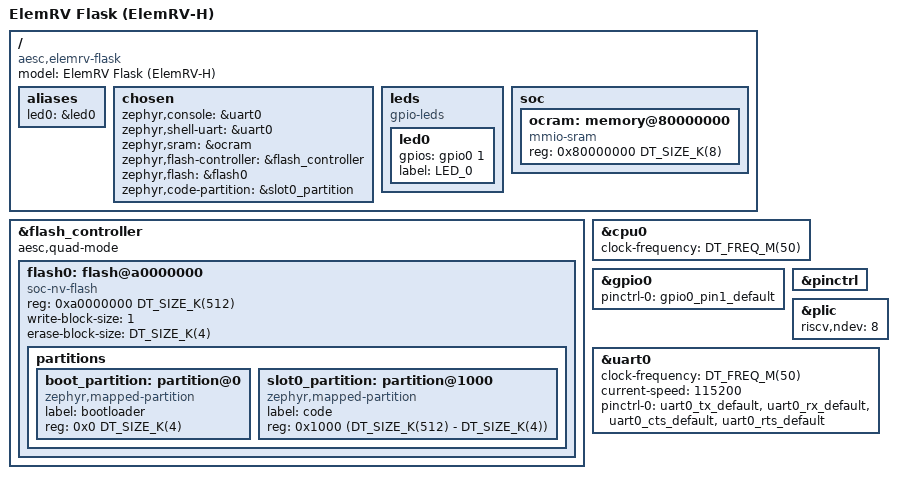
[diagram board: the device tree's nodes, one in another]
/*
 * SPDX-FileCopyrightText: 2026 Aesc Silicon
 *
 * SPDX-License-Identifier: Apache-2.0
 */

/dts-v1/;

#include <aesc/elemrv-h.dtsi>
#include <zephyr/dt-bindings/pwm/pwm.h>
#include "elemrv_flask_elemrv_h-pinctrl.dtsi"

/ {
	model = "ElemRV Flask (ElemRV-H)";
	compatible = "aesc,elemrv-flask";

	aliases {
		led0 = &led0;
	};

	chosen {
		zephyr,console = &uart0;
		zephyr,shell-uart = &uart0;
		zephyr,sram = &ocram;
		zephyr,flash-controller = &flash_controller;
		zephyr,flash = &flash0;
		zephyr,code-partition = &slot0_partition;
	};

	leds: leds {
		compatible = "gpio-leds";

		led0: led0 {
			gpios = <&gpio0 1 GPIO_ACTIVE_HIGH>;
			label = "LED_0";
		};
	};

	soc {
		ocram: memory@80000000 {
			device_type = "memory";
			compatible = "mmio-sram";
			reg = <0x80000000 DT_SIZE_K(8)>;
		};
	};
};

&flash_controller {
	aesc,quad-mode;

	flash0: flash@a0000000 {
		compatible = "soc-nv-flash";
		reg = <0xa0000000 DT_SIZE_K(512)>;
		write-block-size = <1>;
		erase-block-size = <DT_SIZE_K(4)>;
		/* Map the partition offset space onto the XIP window. */
		ranges = <0x0 0xa0000000 DT_SIZE_K(512)>;
		#address-cells = <1>;
		#size-cells = <1>;

		partitions {
			ranges;
			#address-cells = <1>;
			#size-cells = <1>;

			boot_partition: partition@0 {
				compatible = "zephyr,mapped-partition";
				label = "bootloader";
				reg = <0x0 DT_SIZE_K(4)>;
			};

			slot0_partition: partition@1000 {
				compatible = "zephyr,mapped-partition";
				label = "code";
				reg = <0x1000 (DT_SIZE_K(512) - DT_SIZE_K(4))>;
			};
		};
	};
};

&cpu0 {
	clock-frequency = <DT_FREQ_M(50)>;
};

&gpio0 {
	pinctrl-0 = <&gpio0_pin1_default>;
	pinctrl-names = "default";
	status = "okay";
};

&pinctrl {
	status = "okay";
};

&plic {
	riscv,ndev = <8>;
};

&uart0 {
	clock-frequency = <DT_FREQ_M(50)>;
	current-speed = <115200>;
	pinctrl-0 = <&uart0_tx_default
		     &uart0_rx_default
		     &uart0_cts_default
		     &uart0_rts_default>;
	pinctrl-names = "default";
	status = "okay";
};
